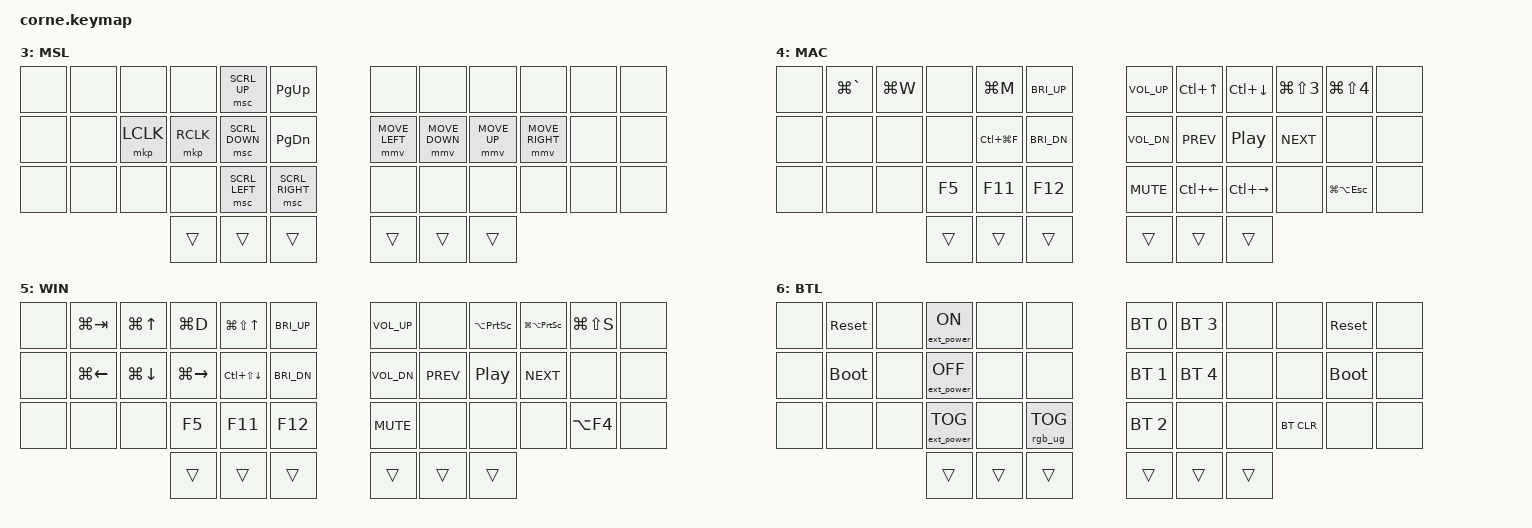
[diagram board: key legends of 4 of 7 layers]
/*
 * Copyright (c) 2020 The ZMK Contributors
 *
 * SPDX-License-Identifier: MIT
 */

#define ZMK_POINTING_DEFAULT_MOVE_VAL 3200
#define ZMK_POINTING_DEFAULT_SCROLL_VAL 720

#include <behaviors.dtsi>
#include <dt-bindings/zmk/keys.h>
#include <dt-bindings/zmk/bt.h>
#include <dt-bindings/zmk/pointing.h>
#include <dt-bindings/zmk/rgb.h>
#include <dt-bindings/zmk/ext_power.h>

#define HRML(k1, k2, k3, k4) &ht LSHFT k1 &ht LALT k2 &ht LCTRL k3 &ht LGUI k4 
#define HRMR(k1, k2, k3, k4) &ht RGUI k1 &ht RCTRL k2 &ht RALT k3 &ht RSHIFT k4 

/ {
        behaviors { 
                ht: hold_tap {
                  compatible = "zmk,behavior-hold-tap";
                  #binding-cells = <2>;
                  flavor = "tap-preferred";
                  tapping-term-ms = <220>;
                  quick-tap-ms = <150>;
                  require-prior-idle-ms = <100>;
                  bindings = <&kp>, <&kp>;
                };
        };

        combos {
                compatible = "zmk,combos";
                combo_esc {
                  timeout-ms = <50>;
                  key-positions = <1 2>;
                  bindings = <&kp ESC>;
                };               
        };

        conditional_layers {
                compatible = "zmk,conditional-layers";
                mac_layer {
                  if-layers = <1 3>;
                  then-layer = <4>;
                };

                win_layer {
                  if-layers = <1 2>;
                  then-layer = <5>;
                };

                bt_and_bl {
                  if-layers = <1 2 3>;
                  then-layer = <6>;
                };
        };

        keymap {

                compatible = "zmk,keymap";

                default_layer {
                        display-name = "TOP";
                        bindings = <
   &none &kp Q &kp W &kp E     &kp R     &kp T         &kp Y                  &kp U       &kp I     &kp O   &kp P    &none
   &none HRML(A,   S ,   D,        F)    &kp G         &kp H                  HRMR(J,         K,        L,      SQT) &none
   &none &kp Z &kp X &kp C     &kp V     &kp B         &kp N                  &kp M       &kp COMMA &kp DOT &kp FSLH &none
                     &kp PG_DN &lt 3 TAB &lt 2 BSPC    &mt RC(RS(RALT)) ENTER &lt 1 SPACE &kp PG_UP
                        >;
                };

                right_layer {
                        display-name = "NUM";
                        bindings = <
   &none &none   &kp N1 &kp N2 &kp N3  &kp PG_UP    &kp HOME &mkp LCLK &mkp RCLK &none    &none    &none
   &none HRML(PSCRN, N4,    N5,    N6) &kp PG_DN    &kp LEFT HRMR(DOWN,     UP,  RIGHT,   NUHS)    &none
   &none &none   &kp N7 &kp N8 &kp N9  &kp N0       &kp END  &none     &none     &none    &none    &none
                        &trans &trans  &trans       &trans   &trans    &trans
                        >;
                };

                left_layer {
                        display-name = "SYM";
                        bindings = <
   &none &kp EXCL &kp AT &kp HASH &kp DLLR  &kp PRCNT   &kp ASTRK &kp MINUS  &kp UNDER &kp EQUAL &kp BSLH   &none
   &none HRML(F13,    F14,   F15,     AMPS) &kp CARET   &kp LBKT  HRMR(LPAR,     LBRC,     COLON,    TILDE) &none
   &none &none    &none  &none    &kp GRAVE &kp PLUS    &kp RBKT  &kp RPAR   &kp RBRC  &kp SEMI &kp PIPE    &none
                         &trans   &trans    &trans      &trans    &trans     &trans
                        >;
                };

                mouse_layer {
                        display-name = "MSL";
                        bindings = <
   &none &none &none     &none       &msc SCRL_UP   &kp PG_UP          &none          &none          &none        &none           &none &none
   &none &none &mkp LCLK &mkp RCLK   &msc SCRL_DOWN &kp PG_DN          &mmv MOVE_LEFT &mmv MOVE_DOWN &mmv MOVE_UP &mmv MOVE_RIGHT &none &none
   &none &none &none     &none       &msc SCRL_LEFT &msc SCRL_RIGHT    &none          &none          &none        &none           &none &none
                         &trans      &trans         &trans             &trans         &trans         &trans
                        >;
                };
                mac_layer {
                        display-name = "MAC";
                        bindings = <
   &none &kp LG(GRAVE) &kp LG(W) &none   &kp LG(M)     &kp C_BRI_UP     &kp C_VOL_UP &kp LC(UP)   &kp LC(DOWN)  &kp LG(LS(N3)) &kp LG(LS(N4))  &none
   &none &none         &none     &none   &kp LC(LG(F)) &kp C_BRI_DN     &kp C_VOL_DN &kp C_PREV   &kp C_PP      &kp C_NEXT     &none           &none
   &none &none         &none     &kp F5  &kp F11       &kp F12          &kp C_MUTE   &kp LC(LEFT) &kp LC(RIGHT) &none          &kp LG(LA(ESC)) &none
                                 &trans &trans        &trans            &trans       &trans       &trans
                        >;
                };

                win_layer {
                        display-name = "WIN";
                        bindings = <
   &none &kp LG(TAB)   &kp LG(UP)       &kp LG(D)     &kp LG(LS(UP))   &kp C_BRI_UP     &kp C_VOL_UP &none      &kp LA(PSCRN) &kp LG(LA(PSCRN)) &kp LG(LS(S)) &none
   &none &kp LG(LEFT)  &kp LG(DOWN)     &kp LG(RIGHT) &kp LC(LS(DOWN)) &kp C_BRI_DN     &kp C_VOL_DN &kp C_PREV &kp C_PP      &kp C_NEXT        &none         &none
   &none &none         &none            &kp F5        &kp F11          &kp F12          &kp C_MUTE   &none      &none         &none             &kp LA(F4)    &none
                                        &trans        &trans           &trans           &trans       &trans       &trans
                        >;
                };

                bt_and_bl {
                        display-name = "BTL";
                        bindings = <
   &none &sys_reset   &none &ext_power EP_ON   &none  &none                   &bt BT_SEL 0 &bt BT_SEL 3 &none  &none        &sys_reset  &none
   &none &bootloader  &none &ext_power EP_OFF  &none  &none                   &bt BT_SEL 1 &bt BT_SEL 4 &none  &none        &bootloader &none
   &none &none        &none &ext_power EP_TOG  &none  &rgb_ug RGB_TOG         &bt BT_SEL 2 &none        &none  &bt BT_CLR   &none       &none
                            &trans &trans &trans                  &trans       &trans       &trans
                        >;
                };
    
    };


};
